# GD32H75E register map
File version: 1.0
CPU: CM7 r1p2, little endian, MPU, FPU, 4 interrupt priority bits
Registers are 32-bit, read-write, reset 0x0 unless marked. A register's access mark holds for its fields unless they carry their own. Offsets are from the block's base; [hi:lo] are bit positions; {n}, {i} and the like mark numbered series.

## EFUSE — Electronic fuse
Base 0x40022800
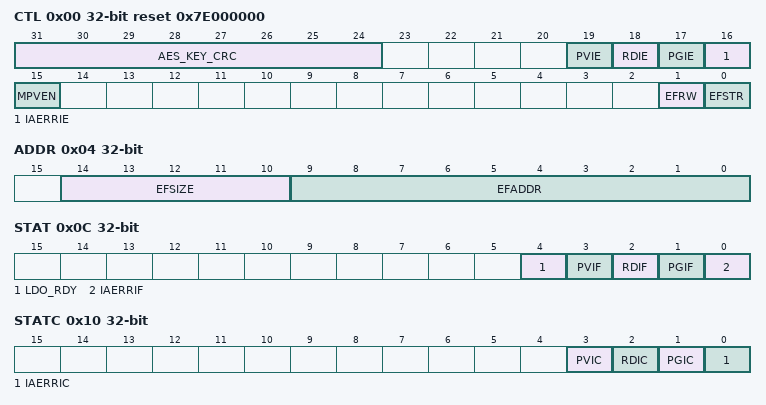
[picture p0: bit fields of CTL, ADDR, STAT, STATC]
0x00 CTL access per field reset 0x7E000000 — Control register
  [31:24] AES_KEY_CRC ro — 8-bits CRC calculation result value of AES key bits
  [19] PVIE rw — Program voltage setting error interrupt enable
  [18] RDIE rw — Read completed interrupt enable
  [17] PGIE rw — Program completed interrupt enable
  [16] IAERRIE rw — Illegal access error interrupt enable
  [15] MPVEN rw — Monitor program voltage function enable
  [1] EFRW rw — The selection of EFUSE operation
  [0] EFSTR rw — Start EFUSE operation
0x04 ADDR — Address register
  [14:10] EFSIZE — Read or write EFUSE data size
  [9:0] EFADDR — Read or write EFUSE data start address
0x0C STAT ro — Status register
  [4] LDO_RDY — EFUSE LDO ready signal
  [3] PVIF — Program voltage setting error flag
  [2] RDIF — Read completed flag
  [1] PGIF — Program completed flag
  [0] IAERRIF — Illegal access error flag
0x10 STATC — Status flag clear register
  [3] PVIC — Clear bit for program voltage setting error interrupt flag
  [2] RDIC — Clear bit for read completed interrupt flag
  [1] PGIC — Clear bit for program completed interrupt flag
  [0] IAERRIC — Clear bit for illegal access error interrupt flag
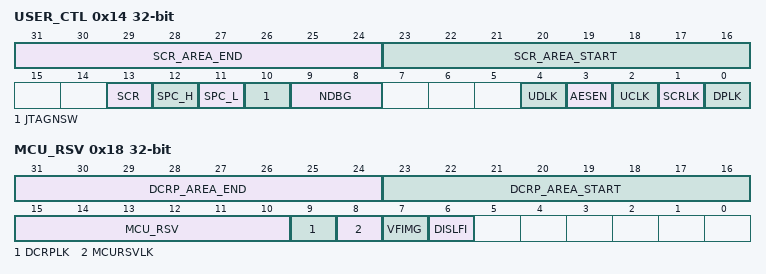
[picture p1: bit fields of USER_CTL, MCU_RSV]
0x14 USER_CTL — User control register
  [31:24] SCR_AREA_END — Secure user area end address bits
  [23:16] SCR_AREA_START — Secure user area start address bits
  [13] SCR — Secure mode enable
  [12] SPC_H — Configure security protection to level high
  [11] SPC_L — Configure security protection to level low
  [10] JTAGNSW — SW or JTAG debugger select
  [9:8] NDBG — Debugging permission setting
  [4] UDLK — EFUSE_USER_DATAx register lock bit
  [3] AESEN — Lock EFUSE_AES_KEYx register and enable AES decrypt function
  [2] UCLK — Low 16 bits of EFUSE_USER_CTL register lock bit
  [1] SCRLK — Secure userarea address lock bit
  [0] DPLK — EFUSE_DPx register lock bit
0x18 MCU_RSV — MCU reserved register
  [31:24] DCRP_AREA_END — DCRP area end address bits
  [23:16] DCRP_AREA_START — DCRP area start address bits
  [15:10] MCU_RSV — MCU reserved data
  [9] DCRPLK — DCRP area address lock bit
  [8] MCURSVLK — Low 16 bits of EFUSE_MCU_RSV register lock bit
  [7] VFIMG — Firmware image verification enable bit
  [6] DISLFI — Licensed firmware install ( LFI ) disable
0x1C DP0 — Debug password register 0
  [31:0] DP — EFUSE debug password value.
0x20 DP1 — Debug password register 1
  [31:0] DP — EFUSE debug password value.
{0x24+4i} AES_KEY{i} wo (i=0..3) — Firmware AES key register {i}
  [31:0] AESKEY — EFUSE AES key value.
{0x34+4i} USER_DATA{i} (i=0..3) — User data register {i}
  [31:0] USERDATA — EFUSE USER_DATA value.

## EXTI — External interrupt/event controller
Base 0x58000000
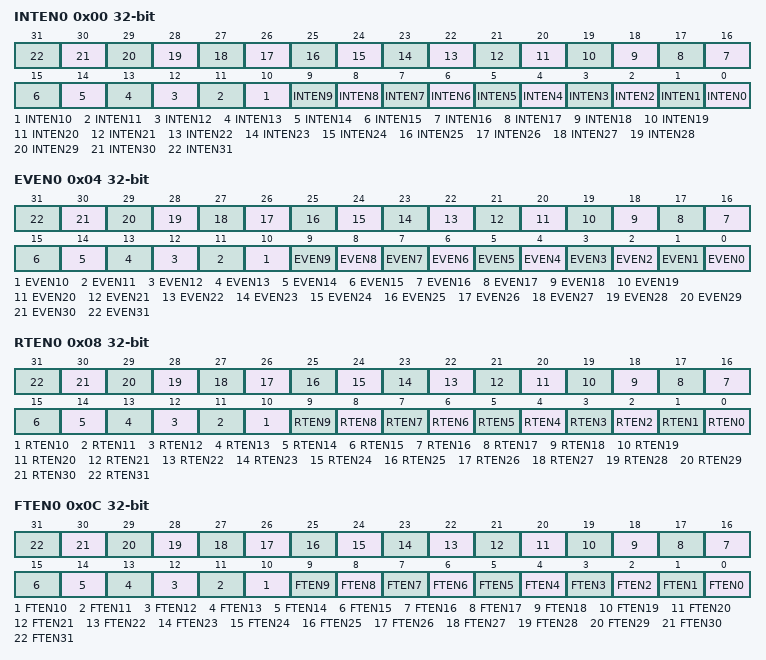
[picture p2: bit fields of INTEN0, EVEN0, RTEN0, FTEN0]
0x00 INTEN0 — Interrupt enable register 0(EXTI_INTEN0)
  [n] INTEN{n} (n=0..31) — Enable Interrupt on line {n}
0x04 EVEN0 — Event enable register 0 (EXTI_EVEN0)
  [n] EVEN{n} (n=0..31) — Enable Event on line {n}
0x08 RTEN0 — Rising Edge Trigger Enable register 0 (EXTI_RTEN0)
  [n] RTEN{n} (n=0..31) — Rising edge trigger enable of line {n}
0x0C FTEN0 — Falling Egde Trigger Enable register 0 (EXTI_FTEN0)
  [n] FTEN{n} (n=0..31) — Falling edge trigger enable of line {n}
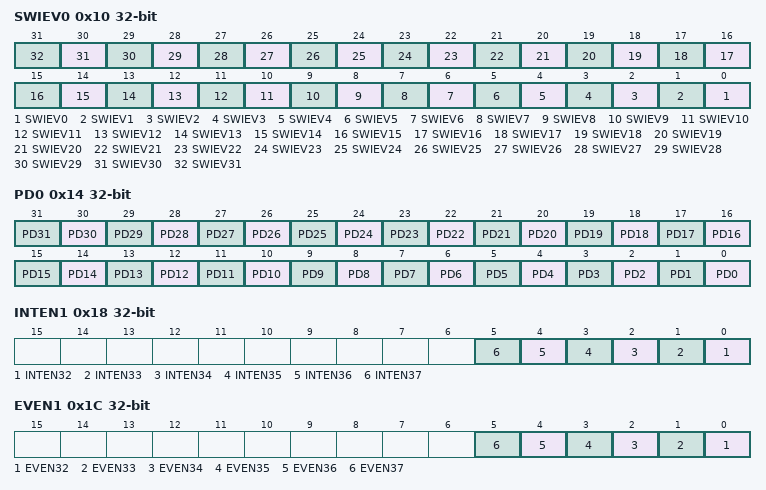
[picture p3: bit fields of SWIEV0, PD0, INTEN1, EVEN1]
0x10 SWIEV0 — Software interrupt event register (EXTI_SWIEV0)
  [n] SWIEV{n} (n=0..31) — Interrupt/Event software trigger on line {n}
0x14 PD0 — Pending register (EXTI_PD0)
  [n] PD{n} (n=0..31) — Interrupt pending status of line {n}
0x18 INTEN1 — Interrupt enable register 0 (EXTI_INTEN1)
  [n-32] INTEN{n} (n=32..37) — Enable Interrupt on line {n}
0x1C EVEN1 — Event enable register 1 (EXTI_EVEN1)
  [n-32] EVEN{n} (n=32..37) — Enable Event on line {n}
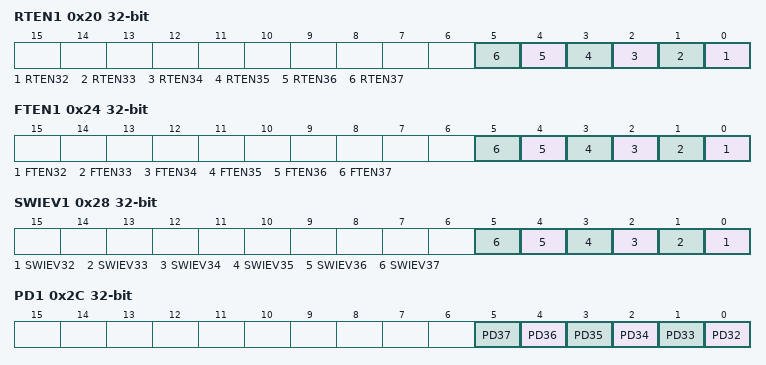
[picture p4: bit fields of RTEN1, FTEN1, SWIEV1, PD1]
0x20 RTEN1 — Rising Edge Trigger Enable register 1 (EXTI_RTEN1)
  [n-32] RTEN{n} (n=32..37) — Rising edge trigger enable of line {n}
0x24 FTEN1 — Falling Egde Trigger Enable register 1 (EXTI_FTEN1)
  [n-32] FTEN{n} (n=32..37) — Falling edge trigger enable of line {n}
0x28 SWIEV1 — Software interrupt event register (EXTI_SWIEV1)
  [n-32] SWIEV{n} (n=32..37) — Interrupt/Event software trigger on line {n}
0x2C PD1 — Pending register (EXTI_PD1)
  [n-32] PD{n} (n=32..37) — Interrupt pending status of line {n}
